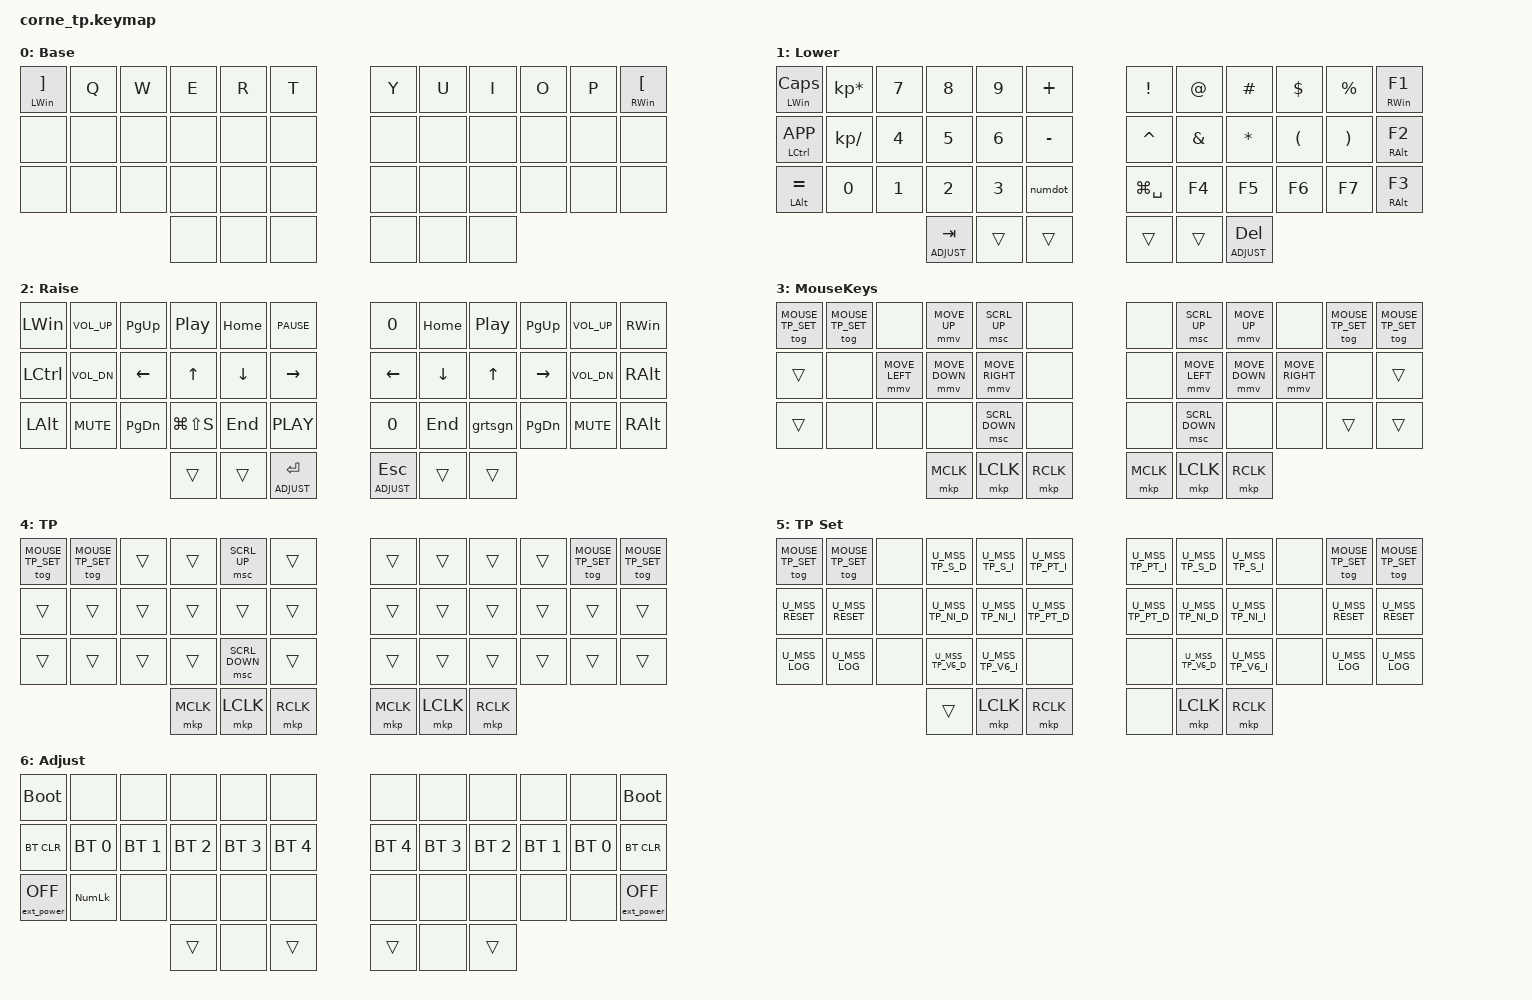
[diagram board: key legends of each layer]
/*
 * Copyright (c) 2020 The ZMK Contributors
 *
 * SPDX-License-Identifier: MIT
 */

#include <behaviors.dtsi>
#include <dt-bindings/zmk/keys.h>
#include <dt-bindings/zmk/bt.h>

#include <dt-bindings/zmk/ext_power.h>

#define BASE 0
#define LOWER 1
#define RAISE 2
#define MOUSE_KEYS 3
#define MOUSE_TP 4
#define MOUSE_TP_SET 5
#define ADJUST 6

/*
 * Defines to enable/disable features
 *
 * These defines allow us to conditionally enable and disable parts of the keymap config.
 *
 * For example, if we decide to build the firmware without the mouse features, we can
 * disable all the config options that rely on those forks and modules without having
 * to edit the entire keymap file manually every time.
 */

#define HAS_MOUSE_KEYS
#define HAS_MOUSE_TP

#ifdef HAS_MOUSE_KEYS
  #include <dt-bindings/zmk/mouse.h>
  #include <behaviors/mouse_keys.dtsi>
#endif  // HAS_MOUSE_KEYS

#ifdef HAS_MOUSE_TP
  // We store the trackpoint settings in a separate file
  // to make organization a little easier.
  #include "mouse_tp.dtsi"
#endif  // HAS_MOUSE_TP



// Adjust layer keys based on enabled features.
//
// This prevents build errors when we build the firmware
// without the mouse keys PR or the TP module.
#ifdef HAS_MOUSE_KEYS
  #define U_THUMB_INNER &mo MOUSE_KEYS
#else
  #define U_THUMB_INNER &none
#endif  // HAS_MOUSE_KEYS

#ifdef HAS_MOUSE_TP
  #define U_TOG_TP_SET &tog MOUSE_TP_SET
#else
  #define U_TOG_TP_SET &none
#endif  // HAS_MOUSE_TP

/ {
    macros {
        numdot: numdot {
            label = "ZM_numdot";
            compatible = "zmk,behavior-macro";
            #binding-cells = <0>;
            wait-ms = <40>;
            tap-ms = <40>;
            bindings
                = <&macro_press   &kp LALT>
                , <&macro_tap     &kp KP_N4 &kp KP_N6>
                , <&macro_release &kp LALT>
                ;
        };
        grtsgn: grtsgn {
            label = "ZM_grtsgn";
            compatible = "zmk,behavior-macro";
            #binding-cells = <0>;
            wait-ms = <40>;
            tap-ms = <40>;
            bindings
                = <&macro_press   &kp LALT>
                , <&macro_tap     &kp KP_N6 &kp KP_N2>
                , <&macro_release &kp LALT>
                ;
        };
    };
};
/ {
  keymap {
    compatible = "zmk,keymap";

    Base_layer {
      display-name = "Base";
// ------------------------------------------------------------------------------------------------
//| LGUI/] |  Q  |  W  |  E  |  R  |  T  |   |  Y  |  U   |  I  |  O  |  P  | RGUI/[ |
//| CTRL/` |  A  |  S  |  D  |  F  |  G  |   |  H  |  J   |  K  |  L  |  ;  | CTRL/' |
//| LALT/\ |  Z  |  X  |  C  |  V  |  B  |   |  N  |  M   |  ,  |  .  |  /  | RALT/- |
//                             | RAISE | SPC | LOWER |   | LOWER | BKSP | RAISE |
      bindings = <
  &mt LWIN RBKT   &kp Q &kp W &kp E &kp R &kp T               &kp Y  &kp U  &kp I     &kp O   &kp P    &mt RWIN LBKT
  &none            &none &none &none &none &none               &none  &none  &none     &none   &none    &none
  &none            &none &none &none &none &none               &none  &none  &none     &none   &none    &none
        &none &none &none                                           &none &none &none
                        >;
    };


    Lower_layer {
      display-name = "Lower";
// -----------------------------------------------------------------------------------------
//|LGUI/CAPS |  *  |  7 |  8  |  9  |  +  |    |  !  |  @  |  #  |  $  |  %  | RGUI/F1 |
//|CTRL/MENU |  /  |  4 |  5  |  6  |  -  |    |  ^  |  &  |  *  |  (  |  )  | CTRL/F2 |
//|  LALT/=  |  0  |  1 |  4  |  3  |  .  |    |  ls |  F4 |  F5 |  F6 |  F7 | RALT/F3 |
//                      | ADJ | ___ | ___ |    | ___ | ___ | ADJ |
      bindings = <
 &mt LWIN CAPS   &kp KP_MULTIPLY  &kp N7 &kp N8   &kp N9      &kp PLUS                    &kp EXCL      &kp AT    &kp HASH   &kp DLLR  &kp PRCNT &mt RWIN F1
 &mt LCTRL K_APP &kp KP_SLASH     &kp N4 &kp N5   &kp N6      &kp MINUS                   &kp CARET     &kp AMPS  &kp STAR   &kp LPAR  &kp RPAR  &mt RALT F2
 &mt LALT EQUAL  &kp N0           &kp N1 &kp N2   &kp N3      &numdot                     &kp LG(SPACE) &kp F4    &kp F5     &kp F6    &kp F7    &mt RALT F3
                                                  &lt ADJUST TAB &trans &trans        &trans &trans        &lt ADJUST DEL
                        >;
    };
    Raise_layer {
    display-name = "Raise";
// -----------------------------------------------------------------------------------------
//| LGUI |  VOLU  |  PGUP  | PLAY | HOME | ___  |            | ___  | HOME | PLAY| PGUP | VOLU | RGUI |
//| CTRL |  VOLD  |  LEFT  |  UP  | DOWN | RGHT |            | RGHT | DOWN | UP  | LEFT | VOLD | CTRL |
//| LALT |  MUTE  |  PGDN  |  ___ | END  | ___  |            | ___  | END  | ___ | PGDN | MUTE | RALT |
//                          | ___ | ___  | ADJ  |            | ADJ  | ___  | ___ |
                        bindings = <
&kp LWIN   &kp C_VOL_UP   &kp PG_UP  &kp C_PP       &kp HOME &kp C_PAUSE                                 &kp N0    &kp HOME  &kp C_PP    &kp PG_UP  &kp C_VOL_UP  &kp RWIN
&kp LCTRL  &kp C_VOL_DN   &kp LEFT   &kp UP         &kp DOWN &kp RIGHT                                   &kp LEFT  &kp DOWN  &kp UP      &kp RIGHT  &kp C_VOL_DN  &kp RALT
&kp LALT   &kp C_MUTE     &kp PG_DN  &kp LG(LS(S))  &kp END  &kp C_PLAY                                  &kp N0    &kp END   &grtsgn      &kp PG_DN  &kp C_MUTE    &kp RALT
                                                    &trans   &trans       &lt ADJUST RET        &lt ADJUST ESC &trans &trans
                        >;
                };

#ifdef HAS_MOUSE_KEYS

    MouseKeys_layer {
      display-name = "MouseKeys";
      bindings = <
// ╭────────────────────────┬────────────────────────┬────────────────────────┬────────────────────────┬────────────────────────┬────────────────────────╮    ╭────────────────────────┬────────────────────────┬────────────────────────┬────────────────────────┬────────────────────────┬────────────────────────╮
     U_TOG_TP_SET             U_TOG_TP_SET             &none                    &mmv MOVE_UP             &msc SCRL_UP             &none                         &none                    &msc SCRL_UP             &mmv MOVE_UP             &none                    U_TOG_TP_SET              U_TOG_TP_SET
// ├────────────────────────┼────────────────────────┼────────────────────────┼────────────────────────┼────────────────────────┼────────────────────────┤    ├────────────────────────┼────────────────────────┼────────────────────────┼────────────────────────┼────────────────────────┼────────────────────────┤
     &trans                   &none                    &mmv MOVE_LEFT           &mmv MOVE_DOWN           &mmv MOVE_RIGHT          &none                         &none                    &mmv MOVE_LEFT           &mmv MOVE_DOWN           &mmv MOVE_RIGHT          &none                     &trans
// ├────────────────────────┼────────────────────────┼────────────────────────┼────────────────────────┼────────────────────────┼────────────────────────┤    ├────────────────────────┼────────────────────────┼────────────────────────┼────────────────────────┼────────────────────────┼────────────────────────┤
     &trans                   &none                    &none                    &none                    &msc SCRL_DOWN           &none                         &none                    &msc SCRL_DOWN           &none                    &none                    &trans                    &trans
// ╰────────────────────────┴────────────────────────┴────────────────────────┴────────────────────────┼────────────────────────┼────────────────────────┤    ├────────────────────────┼────────────────────────┼────────────────────────┼────────────────────────┴────────────────────────┼────────────────────────╯
                                                                                &mkp MCLK                &mkp LCLK                &mkp RCLK                     &mkp MCLK                &mkp LCLK                &mkp RCLK
//                                                                            ╰────────────────────────┴────────────────────────┴────────────────────────╯    ╰────────────────────────┴────────────────────────┴────────────────────────╯
      >;
    };

#endif

#ifdef HAS_MOUSE_TP

    // Automatically activated when the mouse or trackpoint moves.
    // Configured in `include/mouse_tp.dtsi`.
    MouseTP_layer {
      display-name = "TP";
      bindings = <
// ╭────────────────────────┬────────────────────────┬────────────────────────┬────────────────────────┬────────────────────────┬────────────────────────╮    ╭────────────────────────┬────────────────────────┬────────────────────────┬────────────────────────┬────────────────────────┬────────────────────────╮
     U_TOG_TP_SET             U_TOG_TP_SET             &trans                   &trans                   &msc SCRL_UP             &trans                        &trans                   &trans                   &trans                   &trans                   U_TOG_TP_SET              U_TOG_TP_SET
// ├────────────────────────┼────────────────────────┼────────────────────────┼────────────────────────┼────────────────────────┼────────────────────────┤    ├────────────────────────┼────────────────────────┼────────────────────────┼────────────────────────┼────────────────────────┼────────────────────────┤
     &trans                   &trans                   &trans                   &trans                   &trans                   &trans                        &trans                   &trans                   &trans                   &trans                   &trans                    &trans
// ├────────────────────────┼────────────────────────┼────────────────────────┼────────────────────────┼────────────────────────┼────────────────────────┤    ├────────────────────────┼────────────────────────┼────────────────────────┼────────────────────────┼────────────────────────┼────────────────────────┤
     &trans                   &trans                   &trans                   &trans                   &msc SCRL_DOWN           &trans                        &trans                   &trans                   &trans                   &trans                   &trans                    &trans
// ╰────────────────────────┴────────────────────────┴────────────────────────┴────────────────────────┼────────────────────────┼────────────────────────┤    ├────────────────────────┼────────────────────────┼────────────────────────┼────────────────────────┴────────────────────────┼────────────────────────╯
                                                                                &mkp MCLK                &mkp LCLK                &mkp RCLK                     &mkp MCLK                &mkp LCLK                &mkp RCLK
//                                                                            ╰────────────────────────┴────────────────────────┴────────────────────────╯    ╰────────────────────────┴────────────────────────┴────────────────────────╯
      >;
    };

    // You can find the defines for the actual key press behaviors in `include/mouse_tp.dtsi`.
    MouseSettings_layer {
      display-name = "TP Set";
      bindings = <
// ╭────────────────────────┬────────────────────────┬────────────────────────┬────────────────────────┬────────────────────────┬────────────────────────╮    ╭────────────────────────┬────────────────────────┬────────────────────────┬────────────────────────┬────────────────────────┬────────────────────────╮
     U_TOG_TP_SET             U_TOG_TP_SET             &none                    U_MSS_TP_S_D             U_MSS_TP_S_I             U_MSS_TP_PT_I                 U_MSS_TP_PT_I            U_MSS_TP_S_D             U_MSS_TP_S_I             &none                    U_TOG_TP_SET              U_TOG_TP_SET
// ├────────────────────────┼────────────────────────┼────────────────────────┼────────────────────────┼────────────────────────┼────────────────────────┤    ├────────────────────────┼────────────────────────┼────────────────────────┼────────────────────────┼────────────────────────┼────────────────────────┤
     U_MSS_RESET              U_MSS_RESET              &none                    U_MSS_TP_NI_D            U_MSS_TP_NI_I            U_MSS_TP_PT_D                 U_MSS_TP_PT_D            U_MSS_TP_NI_D            U_MSS_TP_NI_I            &none                    U_MSS_RESET               U_MSS_RESET
// ├────────────────────────┼────────────────────────┼────────────────────────┼────────────────────────┼────────────────────────┼────────────────────────┤    ├────────────────────────┼────────────────────────┼────────────────────────┼────────────────────────┼────────────────────────┼────────────────────────┤
     U_MSS_LOG                U_MSS_LOG                &none                    U_MSS_TP_V6_D            U_MSS_TP_V6_I            &none                         &none                    U_MSS_TP_V6_D            U_MSS_TP_V6_I            &none                    U_MSS_LOG                 U_MSS_LOG
// ╰────────────────────────┴────────────────────────┴────────────────────────┴────────────────────────┼────────────────────────┼────────────────────────┤    ├────────────────────────┼────────────────────────┼────────────────────────┼────────────────────────┴────────────────────────┼────────────────────────╯
                                                                                &trans                   &mkp LCLK                &mkp RCLK                     &none                    &mkp LCLK                &mkp RCLK
//                                                                            ╰────────────────────────┴────────────────────────┴────────────────────────╯    ╰────────────────────────┴────────────────────────┴────────────────────────╯
      >;
    };

#endif

    Adjust_layer {
      display-name = "Adjust";
// -----------------------------------------------------------------------------------------
//| BLDR |     |     |     |     |     |   |     |     |     |     |     | BLDR |
//| BTCLR| BT0 | BT1 | BT2 | BT3 | BT4 |   | BT4 | BT3 | BT2 | BT1 | BT0 | BTCLR|
//|pwrOFF|NUMLK|     |     |     |     |   |     |     |     |     |     |      |
//                   |     |     |     |   |     |     |     |
      bindings = <
&bootloader           &none         &none        &none        &none        &none                             &none        &none        &none        &none        &none         &bootloader
&bt BT_CLR            &bt BT_SEL 0  &bt BT_SEL 1 &bt BT_SEL 2 &bt BT_SEL 3 &bt BT_SEL 4                      &bt BT_SEL 4 &bt BT_SEL 3 &bt BT_SEL 2 &bt BT_SEL 1 &bt BT_SEL 0  &bt BT_CLR
&ext_power EP_OFF     &kp KP_NUMLOCK &none        &none        &none        &none                             &none        &none        &none        &none        &none         &ext_power EP_OFF
                                                              &trans       &none     &trans           &trans &none        &trans
      >;
    };
  };
};
